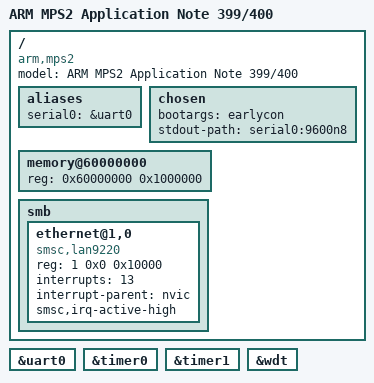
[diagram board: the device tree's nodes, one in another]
/dts-v1/;
#include "mps2.dtsi"
/ {
	model = "ARM MPS2 Application Note 399/400";
	compatible = "arm,mps2";
	aliases {
		serial0 = &uart0;
	};
	chosen {
		bootargs = "earlycon";
		stdout-path = "serial0:9600n8";
	};
	memory@60000000 {
		device_type = "memory";
		reg = <0x60000000 0x1000000>;
	};
	smb {
		ethernet@1,0 {
			compatible = "smsc,lan9220", "smsc,lan9115";
			reg = <1 0x0 0x10000>;
			interrupts = <13>;
			interrupt-parent = <&nvic>;
			smsc,irq-active-high;
		};
	};
};
&uart0 {
	status = "okay";
};
&timer0 {
	status = "okay";
};
&timer1 {
	status = "okay";
};
&wdt {
	status = "okay";
};
